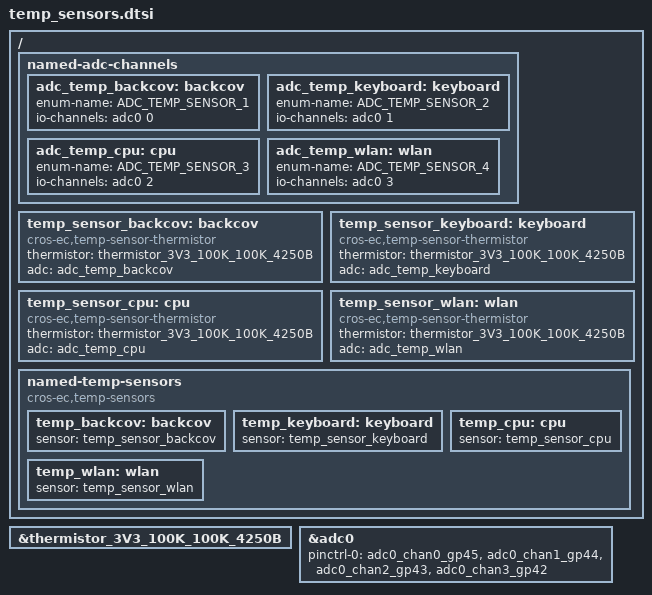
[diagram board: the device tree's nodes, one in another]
/* Copyright 2026 The ChromiumOS Authors
 * Use of this source code is governed by a BSD-style license that can be
 * found in the LICENSE file.
 */

#include <cros/thermistor/thermistor.dtsi>

/ {
	named-adc-channels {

		adc_temp_backcov: backcov {
			enum-name = "ADC_TEMP_SENSOR_1";
			io-channels = <&adc0 0>;
		};
		adc_temp_keyboard: keyboard {
			enum-name = "ADC_TEMP_SENSOR_2";
			io-channels = <&adc0 1>;
		};
		adc_temp_cpu: cpu {
			enum-name = "ADC_TEMP_SENSOR_3";
			io-channels = <&adc0 2>;
		};
		adc_temp_wlan: wlan {
			enum-name = "ADC_TEMP_SENSOR_4";
			io-channels = <&adc0 3>;
		};
	};

	temp_sensor_backcov: backcov {
		compatible = "cros-ec,temp-sensor-thermistor";
		thermistor = <&thermistor_3V3_100K_100K_4250B>;
		adc = <&adc_temp_backcov>;
	};
	temp_sensor_keyboard: keyboard {
		compatible = "cros-ec,temp-sensor-thermistor";
		thermistor = <&thermistor_3V3_100K_100K_4250B>;
		adc = <&adc_temp_keyboard>;
	};
	temp_sensor_cpu: cpu {
		compatible = "cros-ec,temp-sensor-thermistor";
		thermistor = <&thermistor_3V3_100K_100K_4250B>;
		adc = <&adc_temp_cpu>;
	};
	temp_sensor_wlan: wlan {
		compatible = "cros-ec,temp-sensor-thermistor";
		thermistor = <&thermistor_3V3_100K_100K_4250B>;
		adc = <&adc_temp_wlan>;
	};

	named-temp-sensors {
		compatible = "cros-ec,temp-sensors";
		temp_backcov: backcov {
			sensor = <&temp_sensor_backcov>;
		};
		temp_keyboard: keyboard {
			sensor = <&temp_sensor_keyboard>;
		};
		temp_cpu: cpu {
			sensor = <&temp_sensor_cpu>;
		};
		temp_wlan: wlan {
			sensor = <&temp_sensor_wlan>;
		};
	};
};

&thermistor_3V3_100K_100K_4250B {
	status = "okay";
};

&adc0 {
	pinctrl-0 = <&adc0_chan0_gp45
		&adc0_chan1_gp44
		&adc0_chan2_gp43
		&adc0_chan3_gp42>;
	pinctrl-names = "default";
};
